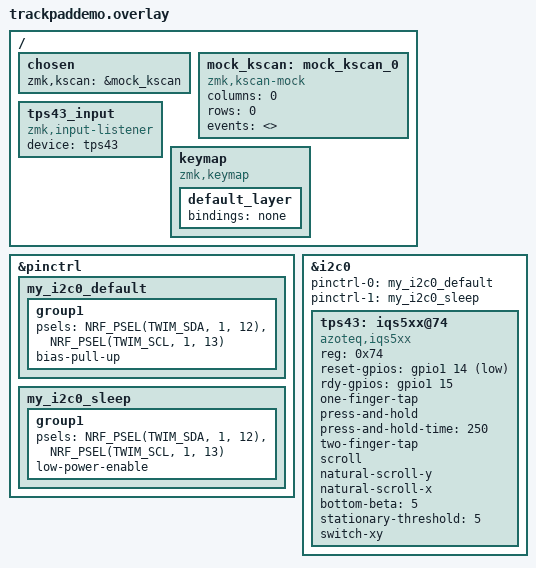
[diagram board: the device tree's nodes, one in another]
#include <behaviors.dtsi>

/ {
    chosen {
        zmk,kscan = &mock_kscan;
    };

    mock_kscan: mock_kscan_0 {
        compatible = "zmk,kscan-mock";
        columns = <0>;
        rows = <0>;
        events = <>;
    };

    tps43_input: tps43_input {
        compatible = "zmk,input-listener";
        device = <&tps43>;
    };

    keymap {
        compatible = "zmk,keymap";
        default_layer {
            bindings = <&none>;
        };
    };
};

&pinctrl {
    my_i2c0_default: my_i2c0_default {
        group1 {
            psels = <NRF_PSEL(TWIM_SDA, 1, 12)>,
                    <NRF_PSEL(TWIM_SCL, 1, 13)>;
            bias-pull-up;
        };
    };

    my_i2c0_sleep: my_i2c0_sleep {
        group1 {
            psels = <NRF_PSEL(TWIM_SDA, 1, 12)>,
                    <NRF_PSEL(TWIM_SCL, 1, 13)>;
            low-power-enable;
        };
    };
};

&i2c0 {
    status = "okay";
    pinctrl-0 = <&my_i2c0_default>;
    pinctrl-1 = <&my_i2c0_sleep>;
    pinctrl-names = "default", "sleep";
    tps43: iqs5xx@74 {
        status = "okay";
        compatible = "azoteq,iqs5xx";
        reg = <0x74>;

        reset-gpios = <&gpio1 14 GPIO_ACTIVE_LOW>;
        rdy-gpios = <&gpio1 15 GPIO_ACTIVE_HIGH>;

        /*
         * Potentially non-exhaustive list of configuration options.
         * See: dts/bindings/input/azoteq,iqs5xx-common.yaml for a full list.
         */
        one-finger-tap;
        press-and-hold;
        press-and-hold-time = <250>;
        two-finger-tap;

        scroll;
        natural-scroll-y;
        natural-scroll-x;

        bottom-beta = <5>;
        stationary-threshold = <5>;

        switch-xy;
    };
};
